AUTOSAR XML (schema 4-2-2)
package /Components
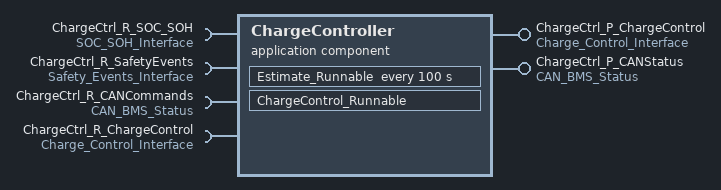
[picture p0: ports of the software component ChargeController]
  application sw component type ChargeController
    provide port ChargeCtrl_P_ChargeControl: provided-interface=Charge_Control_Interface
    provide port ChargeCtrl_P_CANStatus: provided-interface=CAN_BMS_Status
    4 x require port:
      ChargeCtrl_R_SOC_SOH: required-interface=SOC_SOH_Interface
      ChargeCtrl_R_SafetyEvents: required-interface=Safety_Events_Interface
      ChargeCtrl_R_CANCommands: required-interface=CAN_BMS_Status
      ChargeCtrl_R_ChargeControl: required-interface=Charge_Control_Interface
    behavior ChargeController_Behavior
      external trigger occurred event Charge_Request_Event: start-on-event=Receive_Runnable
      timing event Charge_Control_Timer: start-on-event=Estimate_Runnable, period=100
      runnable ChargeControl_Runnable: minimum-start-interval=100, symbol=ChargeControl_Runnable_Symbol
        data-receive-point-by-arguments:
          access Recv_SOC: accessed-variable=ChargeCtrl_R_SOC_SOH.SOC
          access Recv_SafetyEvent: accessed-variable=ChargeCtrl_R_SafetyEvents.SafetyEvent
          access Recv_CANCommand: accessed-variable=ChargeCtrl_R_CANCommands.CANCommand
        data-send-points:
          access Send_ChargeStatus: accessed-variable=ChargeCtrl_P_CANStatus.ChargeStatus
          access Send_ChargeFeedback: accessed-variable=ChargeCtrl_P_ChargeControl.ChargeFeedback
        sync call Call_ChargeHardware_StartStop: operation=ChargeCtrl_R_ChargeControl.StartStopCharge, timeout=200
